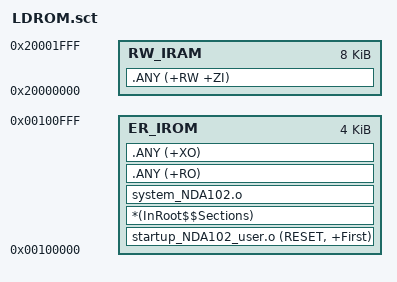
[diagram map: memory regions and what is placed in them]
; *************************************************************
; *** Scatter-Loading Description File generated by uVision ***
; *************************************************************

LR_IROM 0x00100000 0x00001000  {    ; load region size_region
	ER_IROM 0x00100000 0x00001000  {  ; load address = execution address
		startup_NDA102_user.o (RESET, +First)
		*(InRoot$$Sections)
		system_NDA102.o
		.ANY (+RO)
		.ANY (+XO)
	}
	
	RW_IRAM 0x20000000 0x00002000  {  ; RW data
		.ANY (+RW +ZI)
	}
}
